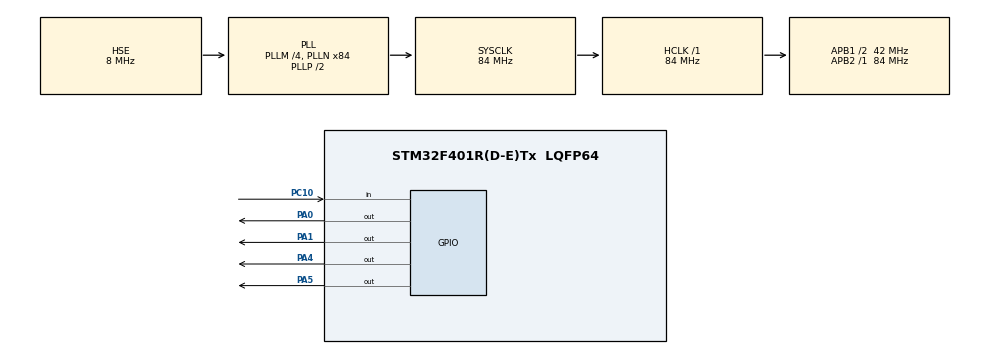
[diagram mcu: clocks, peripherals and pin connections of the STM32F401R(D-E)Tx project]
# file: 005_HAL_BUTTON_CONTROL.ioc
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Mcu.Family=STM32F4
Mcu.Name=STM32F401R(D-E)Tx
Mcu.Package=LQFP64
NVIC.PriorityGroup=NVIC_PRIORITYGROUP_0
PA0-WKUP.GPIO_ModeDefaultOutputPP=GPIO_MODE_OUTPUT_PP
PA0-WKUP.GPIO_PuPd=GPIO_NOPULL
PA0-WKUP.GPIO_Speed=GPIO_SPEED_FREQ_VERY_HIGH
PA0-WKUP.PinState=GPIO_PIN_RESET
PA0-WKUP.Signal=GPIO_Output
PA1.GPIO_ModeDefaultOutputPP=GPIO_MODE_OUTPUT_PP
PA1.GPIO_PuPd=GPIO_NOPULL
PA1.GPIO_Speed=GPIO_SPEED_FREQ_VERY_HIGH
PA1.PinState=GPIO_PIN_RESET
PA1.Signal=GPIO_Output
PA13.Mode=Serial_Wire
PA13.Signal=SYS_JTMS-SWDIO
PA14.Mode=Serial_Wire
PA14.Signal=SYS_JTCK-SWCLK
PA4.GPIO_ModeDefaultOutputPP=GPIO_MODE_OUTPUT_PP
PA4.GPIO_PuPd=GPIO_NOPULL
PA4.GPIO_Speed=GPIO_SPEED_FREQ_VERY_HIGH
PA4.PinState=GPIO_PIN_RESET
PA4.Signal=GPIO_Output
PA5.GPIO_ModeDefaultOutputPP=GPIO_MODE_OUTPUT_PP
PA5.GPIO_PuPd=GPIO_NOPULL
PA5.GPIO_Speed=GPIO_SPEED_FREQ_VERY_HIGH
PA5.PinState=GPIO_PIN_RESET
PA5.Signal=GPIO_Output
PC10.GPIO_PuPd=GPIO_PULLDOWN
PC10.Signal=GPIO_Input
PH0\ -\ OSC_IN.Mode=HSE-External-Oscillator
PH0\ -\ OSC_IN.Signal=RCC_OSC_IN
PH1\ -\ OSC_OUT.Mode=HSE-External-Oscillator
PH1\ -\ OSC_OUT.Signal=RCC_OSC_OUT
ProjectManager.HeapSize=0x200
ProjectManager.StackSize=0x400
ProjectManager.TargetToolchain=TrueSTUDIO
RCC.48MHZClocksFreq_Value=24000000
RCC.AHBFreq_Value=84000000
RCC.APB1CLKDivider=RCC_HCLK_DIV2
RCC.APB1Freq_Value=42000000
RCC.APB1TimFreq_Value=84000000
RCC.APB2Freq_Value=84000000
RCC.APB2TimFreq_Value=84000000
RCC.CortexFreq_Value=84000000
RCC.HCLKFreq_Value=84000000
RCC.HSE_VALUE=8000000
RCC.HSI_VALUE=16000000
RCC.LSE_VALUE=32768
RCC.PLLM=4
RCC.PLLN=84
RCC.PLLQ=7
RCC.PLLSourceVirtual=RCC_PLLSOURCE_HSE
RCC.SYSCLKFreq_VALUE=84000000
RCC.SYSCLKSource=RCC_SYSCLKSOURCE_PLLCLK
RCC.VCOOutputFreq_Value=168000000
board=NUCLEO-F401RE

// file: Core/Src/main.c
/* USER CODE BEGIN Header */

#include "main.h"

/* USER CODE BEGIN PV */
int count=0;
/* USER CODE END PV */

void SystemClock_Config(void);
static void MX_GPIO_Init(void);

int main(void)
{

  /* MCU Configuration--------------------------------------------------------*/

  /* Reset of all peripherals, Initializes the Flash interface and the Systick. */
  HAL_Init();

  /* Configure the system clock */
  SystemClock_Config();

  /* Initialize all configured peripherals */
  MX_GPIO_Init();

  /* Infinite loop */
  while (1)
  {

    /* USER CODE BEGIN 3 */
	  if(HAL_GPIO_ReadPin(GPIOC,GPIO_PIN_10))
	  {
		  while(HAL_GPIO_ReadPin(GPIOC,GPIO_PIN_10));
		  HAL_Delay(100);
		  count++;
	  }
	  if(count % 2 == 1)
	  {
		  HAL_GPIO_WritePin(GPIOA,GPIO_PIN_0|GPIO_PIN_1|GPIO_PIN_4|GPIO_PIN_5,GPIO_PIN_SET);

	  }
	  else
	  {
		  HAL_GPIO_WritePin(GPIOA,GPIO_PIN_0|GPIO_PIN_1|GPIO_PIN_4|GPIO_PIN_5,GPIO_PIN_RESET);
	  }
  }
  /* USER CODE END 3 */
}

void SystemClock_Config(void)
{
  RCC_OscInitTypeDef RCC_OscInitStruct = {0};
  RCC_ClkInitTypeDef RCC_ClkInitStruct = {0};

  /** Configure the main internal regulator output voltage
  */
  __HAL_RCC_PWR_CLK_ENABLE();
  __HAL_PWR_VOLTAGESCALING_CONFIG(PWR_REGULATOR_VOLTAGE_SCALE2);

  /** Initializes the RCC Oscillators according to the specified parameters
  * in the RCC_OscInitTypeDef structure.
  */
  RCC_OscInitStruct.OscillatorType = RCC_OSCILLATORTYPE_HSE;
  RCC_OscInitStruct.HSEState = RCC_HSE_ON;
  RCC_OscInitStruct.PLL.PLLState = RCC_PLL_ON;
  RCC_OscInitStruct.PLL.PLLSource = RCC_PLLSOURCE_HSE;
  RCC_OscInitStruct.PLL.PLLM = 4;
  RCC_OscInitStruct.PLL.PLLN = 84;
  RCC_OscInitStruct.PLL.PLLP = RCC_PLLP_DIV2;
  RCC_OscInitStruct.PLL.PLLQ = 7;
  if (HAL_RCC_OscConfig(&RCC_OscInitStruct) != HAL_OK)
  {
    Error_Handler();
  }

  /** Initializes the CPU, AHB and APB buses clocks
  */
  RCC_ClkInitStruct.ClockType = RCC_CLOCKTYPE_HCLK|RCC_CLOCKTYPE_SYSCLK
                              |RCC_CLOCKTYPE_PCLK1|RCC_CLOCKTYPE_PCLK2;
  RCC_ClkInitStruct.SYSCLKSource = RCC_SYSCLKSOURCE_PLLCLK;
  RCC_ClkInitStruct.AHBCLKDivider = RCC_SYSCLK_DIV1;
  RCC_ClkInitStruct.APB1CLKDivider = RCC_HCLK_DIV2;
  RCC_ClkInitStruct.APB2CLKDivider = RCC_HCLK_DIV1;

  if (HAL_RCC_ClockConfig(&RCC_ClkInitStruct, FLASH_LATENCY_2) != HAL_OK)
  {
    Error_Handler();
  }
}

static void MX_GPIO_Init(void)
{
  GPIO_InitTypeDef GPIO_InitStruct = {0};

  /* GPIO Ports Clock Enable */
  __HAL_RCC_GPIOH_CLK_ENABLE();
  __HAL_RCC_GPIOA_CLK_ENABLE();
  __HAL_RCC_GPIOC_CLK_ENABLE();

  /*Configure GPIO pin Output Level */
  HAL_GPIO_WritePin(GPIOA, GPIO_PIN_0|GPIO_PIN_1|GPIO_PIN_4|GPIO_PIN_5, GPIO_PIN_RESET);

  /*Configure GPIO pins : PA0 PA1 PA4 PA5 */
  GPIO_InitStruct.Pin = GPIO_PIN_0|GPIO_PIN_1|GPIO_PIN_4|GPIO_PIN_5;
  GPIO_InitStruct.Mode = GPIO_MODE_OUTPUT_PP;
  GPIO_InitStruct.Pull = GPIO_NOPULL;
  GPIO_InitStruct.Speed = GPIO_SPEED_FREQ_VERY_HIGH;
  HAL_GPIO_Init(GPIOA, &GPIO_InitStruct);

  /*Configure GPIO pin : PC10 */
  GPIO_InitStruct.Pin = GPIO_PIN_10;
  GPIO_InitStruct.Mode = GPIO_MODE_INPUT;
  GPIO_InitStruct.Pull = GPIO_PULLDOWN;
  HAL_GPIO_Init(GPIOC, &GPIO_InitStruct);

}

void Error_Handler(void)
{
  __disable_irq();
  while (1)
  {
  }
}
